# LPC54102_cm0plus register map
Vendor: nxp.com; File version: 1.0
CPU: CM0PLUS r0p0, little endian, no MPU, no FPU, VTOR, 2 interrupt priority bits
Registers are 32-bit, read-write, reset 0x0 unless marked. A register's access mark holds for its fields unless they carry their own. Offsets are from the block's base; [hi:lo] are bit positions; {n}, {i} and the like mark numbered series; 'fields as' and 'values as' point back to an identical list.

## WWDT — LPC5410x Windowed Watchdog Timer (WWDT)
Base 0x40038000
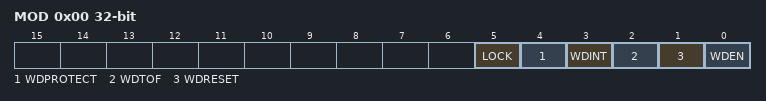
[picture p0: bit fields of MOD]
0x00 MOD — Watchdog mode register. This register contains the basic mode and status of the Watchdog Timer.
  [5] LOCK — Once this bit is set to one and a watchdog feed is performed, disabling or powering down the watchdog oscillator is prevented by hardware. This bit can be set once by software and is only cleared by any reset.
  [4] WDPROTECT — Watchdog update mode. This bit can be set once by software and is only cleared by a reset.
    0=FLEXIBLE (Flexible. The watchdog time-out value (TC) can be changed at any time.); 1=THRESHOLD (Threshold. The watchdog time-out value (TC) can be changed only after the counter is below the value of WDWARNINT and WDWINDOW.)
  [3] WDINT — Warning interrupt flag. Set when the timer reaches the value in WDWARNINT. Cleared by software.
  [2] WDTOF — Watchdog time-out flag. Set when the watchdog timer times out, by a feed error, or by events associated with WDPROTECT. Cleared by software. Causes a chip reset if WDRESET = 1.
  [1] WDRESET — Watchdog reset enable bit. Once this bit has been written with a 1 it cannot be re-written with a 0.
    0=INTERRUPT (Interrupt. A watchdog time-out will not cause a chip reset.); 1=RESET (Reset. A watchdog time-out will cause a chip reset.)
  [0] WDEN — Watchdog enable bit. Once this bit is set to one and a watchdog feed is performed, the watchdog timer will run permanently.
    0=STOP (Stop. The watchdog timer is stopped.); 1=RUN (Run. The watchdog timer is running.)
0x04 TC reset 0xFF — Watchdog timer constant register. This 24-bit register determines the time-out value.
  [23:0] COUNT — Watchdog time-out value.
0x08 FEED wo reset not defined — Watchdog feed sequence register. Writing 0xAA followed by 0x55 to this register reloads the Watchdog timer with the value contained in WDTC.
  [7:0] FEED — Feed value should be 0xAA followed by 0x55.
0x0C TV ro reset 0xFF — Watchdog timer value register. This 24-bit register reads out the current value of the Watchdog timer.
  [23:0] COUNT — Counter timer value.
0x14 WARNINT — Watchdog Warning Interrupt compare value.
  [9:0] WARNINT — Watchdog warning interrupt compare value.
0x18 WINDOW reset 0xFFFFFF — Watchdog Window compare value.
  [23:0] WINDOW — Watchdog window value.

## INPUTMUX — LPC5410x Input multiplexing (INPUT MUX)
Base 0x40050000
{0xC0+4i} PINTSEL[{i}] (i=0..7) — Pin interrupt select register
  [7:0] INTPIN — Pin number select for pin interrupt or pattern match engine input. (PIO0_0 to PIO1_31 correspond to numbers 0 to 63).
{0xE0+4i} DMA_ITRIG_INMUX[{i}] (i=0..21) reset 0x1F — Trigger select register for DMA channel
  [4:0] INP — Trigger input number (decimal value) for DMA channel n (n = 0 to 21). 0 = ADC0 Sequence A interrupt 1 = ADC0 Sequence B interrupt 2 = SCT0 DMA request 0 3 = SCT0 DMA request 1 4 = Timer CTIMER0 Match 0 5 = Timer CTIMER0 Match 1 6 = Timer CTIMER1 Match 0 7 = Timer CTIMER2 Match 0 8 = Timer CTIMER2 Match 1 9 = Timer CTIMER3 Match 0 10 = Timer CTIMER4 Match 0 11 = Timer CTIMER4 Match 1 12 = Pin interrupt 0 13 = Pin interrupt 1 14 = Pin interrupt 2 15 = Pin interrupt 3 16 = DMA output trigger mux 0 17 = DMA output trigger mux 1 18 = DMA output trigger mux 2 19 = DMA output trigger mux 3
{0x140+4i} DMA_OTRIG_INMUX[{i}] (i=0..3) reset 0x1F — DMA output trigger selection to become DMA trigger
  [4:0] INP — DMA trigger output number (decimal value) for DMA channel n (n = 0 to 19).
0x160 FREQMEAS_REF reset 0x1F — Selection for frequency measurement reference clock
  [4:0] CLKIN — Clock source number (decimal value) for frequency measure function target clock: 0 = CLK_IN 1 = FRO 12 MHz oscillator 2 = Watchdog oscillator 3 = 32 kHz RTC oscillator 4 = Main clock (see Section 4.5.23) 5 = PIO0_4 6 = PIO0_20 7 = PIO0_24 8 = PIO1_4
0x164 FREQMEAS_TARGET reset 0x1F — Selection for frequency measurement target clock
  fields as FREQMEAS_REF

## Notices in the file
Copyright 2016-2019 NXP
All rights reserved.
SPDX-License-Identifier: BSD-3-Clause
